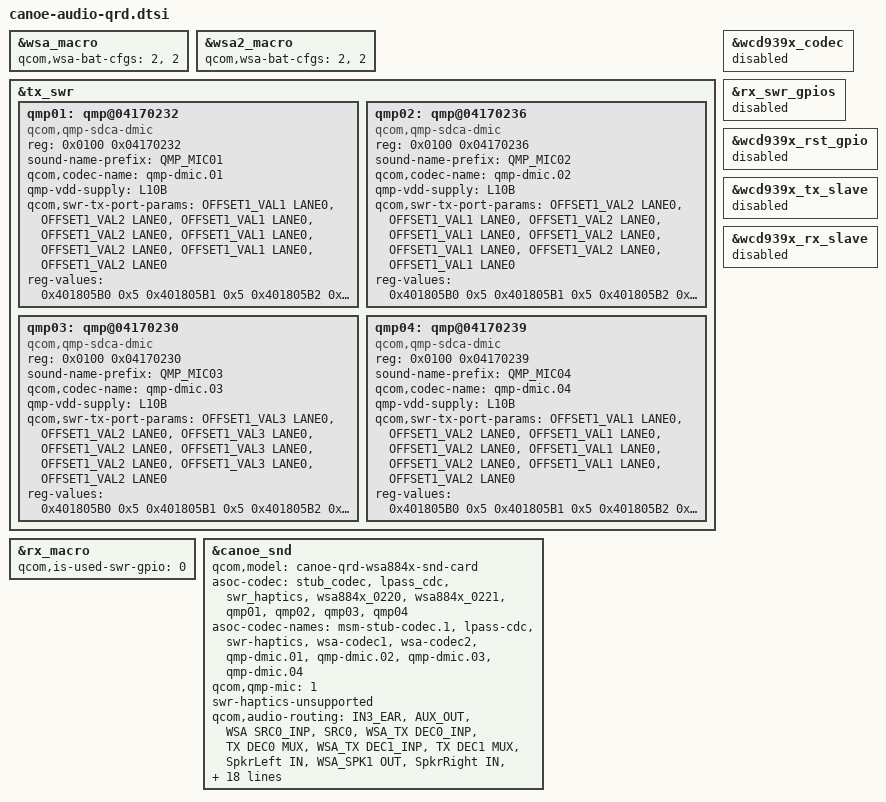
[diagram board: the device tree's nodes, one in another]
// SPDX-License-Identifier: BSD-3-Clause
/*
 * Copyright (c) 2023-2024 Qualcomm Innovation Center, Inc. All rights reserved.
 */

#include "canoe-audio-overlay.dtsi"
#include "canoe-audio-lpass-reg.dtsi"

&wsa_macro {
	qcom,wsa-bat-cfgs = <2>, <2>;
};

&wsa2_macro {
	qcom,wsa-bat-cfgs = <2>, <2>;
};

&tx_swr {
	qmp01: qmp@04170232 {
		/*
		 * reg = <Class_partID[7:0]
		 * partID[15:8] manuID[7:0] manuID[15:8](version4bits_UniqueID4bits)
		 */
		reg = <0x0100 0x04170232>;
		compatible = "qcom,qmp-sdca-dmic";
		sound-name-prefix = "QMP_MIC01";
		qcom,codec-name = "qmp-dmic.01";
		qmp-vdd-supply = <&L10B>;
		qcom,swr-tx-port-params =
				<OFFSET1_VAL1 LANE0>, <OFFSET1_VAL2 LANE0>,
				<OFFSET1_VAL1 LANE0>, <OFFSET1_VAL2 LANE0>,
				<OFFSET1_VAL1 LANE0>, <OFFSET1_VAL2 LANE0>,
				<OFFSET1_VAL1 LANE0>, <OFFSET1_VAL2 LANE0>;
		reg-values = <0x401805B0 0x5
				  0x401805B1 0x5
				  0x401805B2 0x5
				  0x401805B3 0x5
				  0x401805B8 0x5>;
	};

	qmp02: qmp@04170236 {
		reg = <0x0100 0x04170236>;
		compatible = "qcom,qmp-sdca-dmic";
		sound-name-prefix = "QMP_MIC02";
		qcom,codec-name = "qmp-dmic.02";
		qmp-vdd-supply = <&L10B>;
		qcom,swr-tx-port-params =
				<OFFSET1_VAL2 LANE0>, <OFFSET1_VAL1 LANE0>,
				<OFFSET1_VAL2 LANE0>, <OFFSET1_VAL1 LANE0>,
				<OFFSET1_VAL2 LANE0>, <OFFSET1_VAL1 LANE0>,
				<OFFSET1_VAL2 LANE0>, <OFFSET1_VAL1 LANE0>;
		reg-values = <0x401805B0 0x5
				  0x401805B1 0x5
				  0x401805B2 0x5
				  0x401805B3 0x5
				  0x401805B8 0x5>;
	};

	qmp03: qmp@04170230 {
		reg = <0x0100 0x04170230>;
		compatible = "qcom,qmp-sdca-dmic";
		sound-name-prefix = "QMP_MIC03";
		qcom,codec-name = "qmp-dmic.03";
		qmp-vdd-supply = <&L10B>;
		qcom,swr-tx-port-params =
				<OFFSET1_VAL3 LANE0>, <OFFSET1_VAL2 LANE0>,
				<OFFSET1_VAL3 LANE0>, <OFFSET1_VAL2 LANE0>,
				<OFFSET1_VAL3 LANE0>, <OFFSET1_VAL2 LANE0>,
				<OFFSET1_VAL3 LANE0>, <OFFSET1_VAL2 LANE0>;
		reg-values = <0x401805B0 0x5
				  0x401805B1 0x5
				  0x401805B2 0x5
				  0x401805B3 0x5
				  0x401805B8 0x5>;
	};

	qmp04: qmp@04170239 {
		reg = <0x0100 0x04170239>;
		compatible = "qcom,qmp-sdca-dmic";
		sound-name-prefix = "QMP_MIC04";
		qcom,codec-name = "qmp-dmic.04";
		qmp-vdd-supply = <&L10B>;
		qcom,swr-tx-port-params =
				<OFFSET1_VAL1 LANE0>, <OFFSET1_VAL2 LANE0>,
				<OFFSET1_VAL1 LANE0>, <OFFSET1_VAL2 LANE0>,
				<OFFSET1_VAL1 LANE0>, <OFFSET1_VAL2 LANE0>,
				<OFFSET1_VAL1 LANE0>, <OFFSET1_VAL2 LANE0>;
		reg-values = <0x401805B0 0x5
				  0x401805B1 0x5
				  0x401805B2 0x5
				  0x401805B3 0x5
				  0x401805B8 0x5>;
	};
};

&wcd939x_codec {
	status = "disabled";
};

&rx_macro {
	qcom,is-used-swr-gpio = <0>;
};

&rx_swr_gpios {
	status = "disabled";
};

&wcd939x_rst_gpio {
	status = "disabled";
};

&wcd939x_tx_slave {
	status = "disabled";
};

&wcd939x_rx_slave {
	status = "disabled";
};

&canoe_snd {
	qcom,model = "canoe-qrd-wsa884x-snd-card";
	asoc-codec  = <&stub_codec>, <&lpass_cdc>,
			<&swr_haptics>,	<&wsa884x_0220>, <&wsa884x_0221>,
			<&qmp01>, <&qmp02>,
			<&qmp03>, <&qmp04>;
	asoc-codec-names = "msm-stub-codec.1", "lpass-cdc",
		"swr-haptics", "wsa-codec1", "wsa-codec2",
		"qmp-dmic.01", "qmp-dmic.02",
		"qmp-dmic.03", "qmp-dmic.04";
	qcom,qmp-mic = <1>;
	swr-haptics-unsupported;
	qcom,audio-routing =
		"IN3_EAR", "AUX_OUT",
		"WSA SRC0_INP", "SRC0",
		"WSA_TX DEC0_INP", "TX DEC0 MUX",
		"WSA_TX DEC1_INP", "TX DEC1 MUX",
		"SpkrLeft IN", "WSA_SPK1 OUT",
		"SpkrRight IN", "WSA_SPK2 OUT",
		"TX SWR_INPUT", "WCD_TX_OUTPUT",
		"TX SWR_INPUT", "QMP_MIC01 NORMAL_OUTPUT",
		"TX SWR_INPUT", "QMP_MIC02 NORMAL_OUTPUT",
		"TX SWR_INPUT", "QMP_MIC03 NORMAL_OUTPUT",
		"TX SWR_INPUT", "QMP_MIC04 NORMAL_OUTPUT",
		"VA SWR_INPUT", "VA_SWR_CLK",
		"VA SWR_INPUT", "WCD_TX_OUTPUT",
		"VA SWR_INPUT", "QMP_MIC01 LP_OUTPUT",
		"VA SWR_INPUT", "QMP_MIC02 LP_OUTPUT",
		"VA SWR_INPUT", "QMP_MIC03 LP_OUTPUT",
		"VA SWR_INPUT", "QMP_MIC04 LP_OUTPUT",
		"VA SWR_INPUT", "QMP_MIC01 VA_NORMAL_OUTPUT",
		"VA SWR_INPUT", "QMP_MIC02 VA_NORMAL_OUTPUT",
		"VA SWR_INPUT", "QMP_MIC03 VA_NORMAL_OUTPUT",
		"VA SWR_INPUT", "QMP_MIC04 VA_NORMAL_OUTPUT",
		"VA_AIF1 CAP", "VA_SWR_CLK",
		"VA_AIF2 CAP", "VA_SWR_CLK",
		"VA_AIF3 CAP", "VA_SWR_CLK";
	qcom,wcd-disabled = <1>;
};
